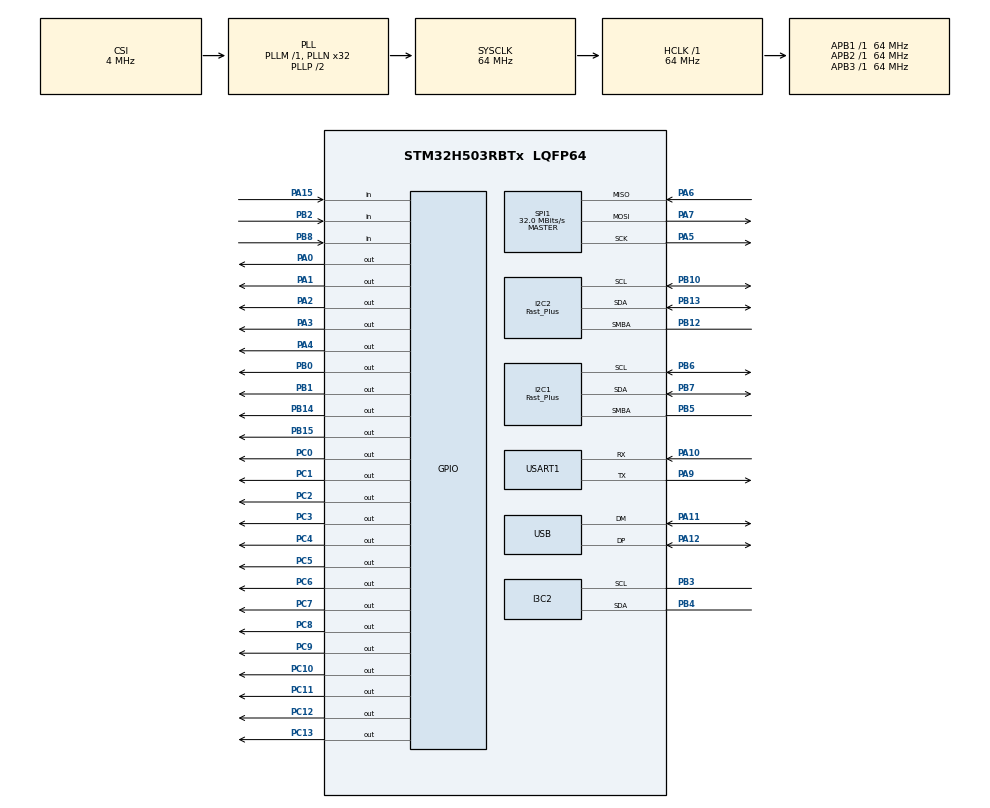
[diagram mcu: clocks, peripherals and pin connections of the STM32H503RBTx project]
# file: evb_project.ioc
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BOOTPATH.BootPathName=LEGACY
BOOTPATH.UserSelectedBootPath=LEGACY
GPDMA1.DIRECTION_GPDMACH0=DMA_MEMORY_TO_PERIPH
GPDMA1.IPHANDLE_GPDMACH0-SIMPLEREQUEST_GPDMACH0=__NULL
GPDMA1.IPHANDLE_GPDMACH1-SIMPLEREQUEST_GPDMACH1=__NULL
GPDMA1.REQUEST_GPDMACH0=GPDMA1_REQUEST_SPI1_TX
GPDMA1.REQUEST_GPDMACH1=GPDMA1_REQUEST_SPI1_RX
I2C1.I2C_Speed_Mode=I2C_Fast_Plus
I2C1.SMBusNoStretchMode=SMBUS_NOSTRETCH_ENABLE
I2C1.Timeout=0x0000830D
I2C1.Timing=0x00300B29
I2C2.I2C_Speed_Mode=I2C_Fast_Plus
I2C2.SMBusNoStretchMode=SMBUS_NOSTRETCH_ENABLE
I2C2.Timeout=0x0000830D
I2C2.Timing=0x00300B29
I3C2.BusFreeDuration=430
I3C2.Register0=0x001e131e
I3C2.Register1=0x000d003e
I3C2.SCLI3CHighDuration=0x13
I3C2.SCLODLowDuration=0x1e
I3C2.SCLPPLowDuration=0x1e
I3C2.SCL_OD_Freq=1255
I3C2.SCL_PP_Freq=1255
I3C2.hexBusFreeDuration=0x0d
I3C2.hexBusIdleDuration=0x3e
Mcu.Family=STM32H5
Mcu.Name=STM32H503RBTx
Mcu.Package=LQFP64
NVIC.GPDMA1_Channel0_IRQn=true\:0\:0\:false\:false\:true\:false\:true\:true
NVIC.GPDMA1_Channel1_IRQn=true\:0\:0\:false\:false\:true\:false\:true\:true
NVIC.I2C1_ER_IRQn=true\:0\:0\:false\:false\:true\:true\:true\:true
NVIC.I2C1_EV_IRQn=true\:0\:0\:false\:false\:true\:true\:true\:true
NVIC.I2C2_ER_IRQn=true\:0\:0\:false\:false\:true\:true\:true\:true
NVIC.I2C2_EV_IRQn=true\:0\:0\:false\:false\:true\:true\:true\:true
NVIC.PriorityGroup=NVIC_PRIORITYGROUP_4
NVIC.SPI1_IRQn=true\:0\:0\:false\:false\:true\:true\:true\:true
NVIC.TIM1_BRK_IRQn=true\:0\:0\:false\:false\:true\:true\:true\:true
NVIC.TIM1_CC_IRQn=true\:0\:0\:false\:false\:true\:true\:true\:true
NVIC.TIM1_TRG_COM_IRQn=true\:0\:0\:false\:false\:true\:true\:true\:true
NVIC.TIM1_UP_IRQn=true\:0\:0\:false\:false\:true\:true\:true\:true
NVIC.USB_DRD_FS_IRQn=true\:0\:0\:false\:false\:true\:true\:true\:true
PA0.Signal=GPIO_Output
PA1.Signal=GPIO_Output
PA10.Mode=Asynchronous
PA10.Signal=USART1_RX
PA11.Mode=Device
PA11.Signal=USB_DM
PA12.Mode=Device
PA12.Signal=USB_DP
PA15(JTDI).Signal=GPIO_Input
PA2.GPIO_PuPd=GPIO_PULLUP
PA2.PinState=GPIO_PIN_SET
PA2.Signal=GPIO_Output
PA3.GPIO_PuPd=GPIO_PULLUP
PA3.PinState=GPIO_PIN_SET
PA3.Signal=GPIO_Output
PA4.GPIO_PuPd=GPIO_PULLUP
PA4.PinState=GPIO_PIN_SET
PA4.Signal=GPIO_Output
PA5.Mode=Full_Duplex_Master
PA5.Signal=SPI1_SCK
PA6.Mode=Full_Duplex_Master
PA6.Signal=SPI1_MISO
PA7.Mode=Full_Duplex_Master
PA7.Signal=SPI1_MOSI
PA9.Mode=Asynchronous
PA9.Signal=USART1_TX
PB0.Signal=GPIO_Output
PB1.Signal=GPIO_Output
PB10.Mode=SMBus-Alert-mode
PB10.Signal=I2C2_SCL
PB12.Mode=SMBus-Alert-mode
PB12.Signal=I2C2_SMBA
PB13.Mode=SMBus-Alert-mode
PB13.Signal=I2C2_SDA
PB14.Signal=GPIO_Output
PB15.Signal=GPIO_Output
PB2.Signal=GPIO_Input
PB3(JTDO/TRACESWO).Mode=Controller
PB3(JTDO/TRACESWO).Signal=I3C2_SCL
PB4(NJTRST).Mode=Controller
PB4(NJTRST).Signal=I3C2_SDA
PB5.Mode=SMBus-Alert-mode
PB5.Signal=I2C1_SMBA
PB6.Mode=SMBus-Alert-mode
PB6.Signal=I2C1_SCL
PB7.Mode=SMBus-Alert-mode
PB7.Signal=I2C1_SDA
PB8.Signal=GPIO_Input
PC0.Signal=GPIO_Output
PC1.Signal=GPIO_Output
PC10.Signal=GPIO_Output
PC11.Signal=GPIO_Output
PC12.Signal=GPIO_Output
PC13.Signal=GPIO_Output
PC14-OSC32_IN(OSC32_IN).Mode=LSE-External-Oscillator
PC14-OSC32_IN(OSC32_IN).Signal=RCC_OSC32_IN
PC15-OSC32_OUT(OSC32_OUT).Mode=LSE-External-Oscillator
PC15-OSC32_OUT(OSC32_OUT).Signal=RCC_OSC32_OUT
PC2.Signal=GPIO_Output
PC3.Signal=GPIO_Output
PC4.Signal=GPIO_Output
PC5.Signal=GPIO_Output
PC6.Signal=GPIO_Output
PC7.Signal=GPIO_Output
PC8.Signal=GPIO_Output
PC9.Signal=GPIO_Output
PH0-OSC_IN(PH0).Mode=HSE-External-Oscillator
PH0-OSC_IN(PH0).Signal=RCC_OSC_IN
PH1-OSC_OUT(PH1).Mode=HSE-External-Oscillator
PH1-OSC_OUT(PH1).Signal=RCC_OSC_OUT
ProjectManager.HeapSize=0x600
ProjectManager.StackSize=0x800
ProjectManager.TargetToolchain=CMake
RCC.ADCFreq_Value=64000000
RCC.AHBFreq_Value=64000000
RCC.APB1Freq_Value=64000000
RCC.APB1TimFreq_Value=64000000
RCC.APB2Freq_Value=64000000
RCC.APB2TimFreq_Value=64000000
RCC.APB3Freq_Value=64000000
RCC.CSI_VALUE=4000000
RCC.CortexFreq_Value=64000000
RCC.EPOD_VALUE=4000000
RCC.HCLKFreq_Value=64000000
RCC.HSE_VALUE=25000000
RCC.HSI48_VALUE=48000000
RCC.HSI_VALUE=64000000
RCC.LSIRC_VALUE=32000
RCC.PLL2FRACN=0
RCC.PLLFRACN=0
RCC.PLLN=32
RCC.SYSCLKFreq_VALUE=64000000
RCC.SYSCLKSource=RCC_SYSCLKSOURCE_PLLCLK
RCC.USBFreq_Value=48000000
RCC.VCOOutputFreq_Value=128000000
SPI1.BaudRatePrescaler=SPI_BAUDRATEPRESCALER_2
SPI1.CLKPhase=SPI_PHASE_2EDGE
SPI1.CalculateBaudRate=32.0 MBits/s
SPI1.DataSize=SPI_DATASIZE_8BIT
SPI1.Direction=SPI_DIRECTION_2LINES
SPI1.Mode=SPI_MODE_MASTER
SPI1.VirtualType=VM_MASTER
TIM1.AutoReloadPreload=TIM_AUTORELOAD_PRELOAD_ENABLE
TIM1.PeriodNoDither=99
TIM1.Prescaler=63999
USART1.VirtualMode-Asynchronous=VM_ASYNC
USB.VirtualMode=Device_Only
VP_BOOTPATH_VS_BOOTPATH.Mode=BP_Activate
VP_CORTEX_M33_NS_VS_Hclk.Mode=Hclk_Mode
VP_GPDMA1_VS_GPDMACH0.Mode=SIMPLEREQUEST_GPDMACH0
VP_GPDMA1_VS_GPDMACH1.Mode=SIMPLEREQUEST_GPDMACH1
VP_MEMORYMAP_VS_MEMORYMAP.Mode=CurAppReg
VP_PWR_VS_LPOM.Mode=PowerOptimisation
VP_PWR_VS_SECSignals.Mode=Security/Privilege
VP_TIM1_VS_ClockSourceINT.Mode=Internal
board=custom

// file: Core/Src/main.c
/* USER CODE BEGIN Header */
/**
  ******************************************************************************
  * @file           : main.c
  * @brief          : Main program body
  ******************************************************************************
  * @attention
  *
  * Copyright (c) 2026 STMicroelectronics.
  * All rights reserved.
  *
  * This software is licensed under terms that can be found in the LICENSE file
  * in the root directory of this software component.
  * If no LICENSE file comes with this software, it is provided AS-IS.
  *
  ******************************************************************************
  */
/* USER CODE END Header */
#include "main.h"

/* USER CODE BEGIN Includes */
#include "stm32h5xx_hal.h"
#include "stm32h5xx_hal_tim.h"
#include "usbd_core.h"
#include "usbd_customhid.h"
#include "usbd_customhid_if.h"
#include "usbd_desc.h"
#include "usbd_composite_builder.h"
#include "stm32h5xx_hal_gpio.h"
#include <stdint.h>
#include <stdio.h>
#include "usb_message_handler.h"
#include "sample_handler.h"

/* USER CODE END Includes */

SMBUS_HandleTypeDef hsmbus1;
SMBUS_HandleTypeDef hsmbus2;

// I3C_HandleTypeDef hi3c2;

SPI_HandleTypeDef hspi1;
DMA_HandleTypeDef handle_GPDMA1_Channel1;
DMA_HandleTypeDef handle_GPDMA1_Channel0;

TIM_HandleTypeDef htim1;

UART_HandleTypeDef huart1;

PCD_HandleTypeDef hpcd_USB_DRD_FS;

void SystemClock_Config(void);
static void MX_GPIO_Init(void);
static void MX_GPDMA1_Init(void);
static void MX_I2C2_SMBUS_Init(void);
static void MX_I2C1_SMBUS_Init(void);
// static void MX_I3C2_Init(void);
static void MX_SPI1_Init(void);
static void MX_TIM1_Init(void);
static void MX_USART1_UART_Init(void);

/* USER CODE BEGIN 0 */

//                   USB
// uint8_t CDC_EpAdd_Inst[3] = {CDC_IN_EP, CDC_OUT_EP, CDC_CMD_EP}; 	/* CDC Endpoint Addresses array */
// uint8_t HID_EpAdd_Inst = HID_EPIN_ADDR;								/* HID Endpoint Address array */
uint8_t CustomHID_EpAdress[2] = {CUSTOM_HID_EPIN_ADDR, CUSTOM_HID_EPOUT_ADDR};								/* HID Endpoint Address array */
USBD_HandleTypeDef hUsbDeviceFS;
// uint8_t hid_report_buffer[SAMPLE_REPORT_SIZE];
uint8_t HID_InstID = 0, CDC_InstID = 0, CUSTOMHID_InstID = 0;
volatile uint8_t current_sampling_enabled = 0;
volatile uint8_t voltage_sampling_enabled = 0;
volatile uint8_t sampling_enabled_once = 0;

/* USER CODE END 0 */

int main(void)
{

  /* MCU Configuration--------------------------------------------------------*/

  /* Reset of all peripherals, Initializes the Flash interface and the Systick. */

  HAL_Init();

  /* Configure the system clock */
  SystemClock_Config();

  /* Initialize all configured peripherals */
  MX_GPIO_Init();
  MX_GPDMA1_Init();
  MX_I2C2_SMBUS_Init();
  MX_I2C1_SMBUS_Init();
  // MX_I3C2_Init();
  MX_SPI1_Init();
  MX_TIM1_Init();
  MX_USART1_UART_Init();
  /* USER CODE BEGIN 2 */

  InitSampleDev();

//                                           USB
  USBD_UsrLog("\r\n=== Welcome to stm32 custom-hid driver! ===");
  /* Initialize the USB Device Library */
  if(USBD_Init(&hUsbDeviceFS, &Class_Desc, 0) != USBD_OK)
    Error_Handler();
  /* Store HID Instance Class ID */
  CUSTOMHID_InstID = hUsbDeviceFS.classId;
  /* Register the HID Class */
#ifdef USE_USBD_COMPOSITE
  if(USBD_RegisterClassComposite(&hUsbDeviceFS, USBD_CUSTOM_HID_CLASS, CLASS_TYPE_CHID, CustomHID_EpAdress) != USBD_OK)
#else
    /* Add Supported Class */
  if(USBD_RegisterClass(&hUsbDeviceFS, &USBD_CUSTOM_HID) != USBD_OK)
#endif /* USE_USBD_COMPOSITE */
    Error_Handler();

#ifdef USE_USBD_COMPOSITE
  /* Add Custom HID Interface Class */
  if (USBD_CMPSIT_SetClassID(&hUsbDeviceFS, CLASS_TYPE_CHID, 0) != 0xFF)
  {
    USBD_CUSTOM_HID_RegisterInterface(&hUsbDeviceFS, &USBD_CustomHID_fops);
  }

  // /* Add CDC Interface Class */
  if (USBD_CMPSIT_SetClassID(&hUsbDeviceFS, CLASS_TYPE_CDC, 0) != 0xFF)
  {
    USBD_CDC_RegisterInterface(&hUsbDeviceFS, &USBD_CDC_Template_fops);
  }
#else
  /* Add Custom HID callbacks */
  USBD_CUSTOM_HID_RegisterInterface(&hUsbDeviceFS, &USBD_CustomHID_fops);

#endif /* USE_USBD_COMPOSITE */

  UsbMsg_Reset();
  USBD_Start(&hUsbDeviceFS);

  /* USER CODE END 2 */

  /* Infinite loop */
  /* USER CODE BEGIN WHILE */
  while (1) {

    while (UsbMsg_ProcessNext()) {
    }

    // if(sampling_enabled_once) {
    //   ClearSampleData();
    //   // SampleCurrentData();
    //   SampleVoltageData();
    //   SendSampleReport();
    //   USBD_ErrLog("Start sampling once ");
    //   sampling_enabled_once = 0;
    // }

    ClearSampleData();

    if (current_sampling_enabled) {
      SampleCurrentData();
    }
    if (voltage_sampling_enabled) {
      SampleVoltageData();
    }

    if(current_sampling_enabled || voltage_sampling_enabled) {
      SendSampleReport();
    }

    /* USER CODE END WHILE */

  }
}

void SystemClock_Config(void)
{
  RCC_OscInitTypeDef RCC_OscInitStruct = {0};
  RCC_ClkInitTypeDef RCC_ClkInitStruct = {0};

  /** Configure the main internal regulator output voltage
  */
  __HAL_PWR_VOLTAGESCALING_CONFIG(PWR_REGULATOR_VOLTAGE_SCALE3);

  while(!__HAL_PWR_GET_FLAG(PWR_FLAG_VOSRDY)) {}

  /** Initializes the RCC Oscillators according to the specified parameters
  * in the RCC_OscInitTypeDef structure.
  */
  RCC_OscInitStruct.OscillatorType = RCC_OSCILLATORTYPE_HSI48|RCC_OSCILLATORTYPE_CSI;
  RCC_OscInitStruct.HSI48State = RCC_HSI48_ON;
  RCC_OscInitStruct.CSIState = RCC_CSI_ON;
  RCC_OscInitStruct.CSICalibrationValue = RCC_CSICALIBRATION_DEFAULT;
  RCC_OscInitStruct.PLL.PLLState = RCC_PLL_ON;
  RCC_OscInitStruct.PLL.PLLSource = RCC_PLL1_SOURCE_CSI;
  RCC_OscInitStruct.PLL.PLLM = 1;
  RCC_OscInitStruct.PLL.PLLN = 32;
  RCC_OscInitStruct.PLL.PLLP = 2;
  RCC_OscInitStruct.PLL.PLLQ = 2;
  RCC_OscInitStruct.PLL.PLLR = 2;
  RCC_OscInitStruct.PLL.PLLRGE = RCC_PLL1_VCIRANGE_2;
  RCC_OscInitStruct.PLL.PLLVCOSEL = RCC_PLL1_VCORANGE_WIDE;
  RCC_OscInitStruct.PLL.PLLFRACN = 0;
  if (HAL_RCC_OscConfig(&RCC_OscInitStruct) != HAL_OK)
  {
    Error_Handler();
  }

  /** Initializes the CPU, AHB and APB buses clocks
  */
  RCC_ClkInitStruct.ClockType = RCC_CLOCKTYPE_HCLK|RCC_CLOCKTYPE_SYSCLK
                              |RCC_CLOCKTYPE_PCLK1|RCC_CLOCKTYPE_PCLK2
                              |RCC_CLOCKTYPE_PCLK3;
  RCC_ClkInitStruct.SYSCLKSource = RCC_SYSCLKSOURCE_PLLCLK;
  RCC_ClkInitStruct.AHBCLKDivider = RCC_SYSCLK_DIV1;
  RCC_ClkInitStruct.APB1CLKDivider = RCC_HCLK_DIV1;
  RCC_ClkInitStruct.APB2CLKDivider = RCC_HCLK_DIV1;
  RCC_ClkInitStruct.APB3CLKDivider = RCC_HCLK_DIV1;

  if (HAL_RCC_ClockConfig(&RCC_ClkInitStruct, FLASH_LATENCY_3) != HAL_OK)
  {
    Error_Handler();
  }

  /** Configure the programming delay
  */
  __HAL_FLASH_SET_PROGRAM_DELAY(FLASH_PROGRAMMING_DELAY_1);
}

static void MX_GPDMA1_Init(void)
{

  /* Peripheral clock enable */
  __HAL_RCC_GPDMA1_CLK_ENABLE();

  /* GPDMA1 interrupt Init */
    HAL_NVIC_SetPriority(GPDMA1_Channel0_IRQn, 0, 0);
    HAL_NVIC_EnableIRQ(GPDMA1_Channel0_IRQn);
    HAL_NVIC_SetPriority(GPDMA1_Channel1_IRQn, 0, 0);
    HAL_NVIC_EnableIRQ(GPDMA1_Channel1_IRQn);

}

static void MX_I2C1_SMBUS_Init(void)
{

  hsmbus1.Instance = I2C1;
  hsmbus1.Init.Timing = 0x00300B29;
  hsmbus1.Init.AnalogFilter = SMBUS_ANALOGFILTER_ENABLE;
  hsmbus1.Init.OwnAddress1 = 2;
  hsmbus1.Init.AddressingMode = SMBUS_ADDRESSINGMODE_7BIT;
  hsmbus1.Init.DualAddressMode = SMBUS_DUALADDRESS_DISABLE;
  hsmbus1.Init.OwnAddress2 = 0;
  hsmbus1.Init.OwnAddress2Masks = SMBUS_OA2_NOMASK;
  hsmbus1.Init.GeneralCallMode = SMBUS_GENERALCALL_DISABLE;
  hsmbus1.Init.NoStretchMode = SMBUS_NOSTRETCH_ENABLE;
  hsmbus1.Init.PacketErrorCheckMode = SMBUS_PEC_DISABLE;
  hsmbus1.Init.PeripheralMode = SMBUS_PERIPHERAL_MODE_SMBUS_SLAVE;
  hsmbus1.Init.SMBusTimeout = 0x0000830D;
  if (HAL_SMBUS_Init(&hsmbus1) != HAL_OK)
  {
    Error_Handler();
  }

  /** configuration Alert Mode
  */
  if (HAL_SMBUS_EnableAlert_IT(&hsmbus1) != HAL_OK)
  {
    Error_Handler();
  }

  /** SMBus Fast mode Plus enable
  */
  if (HAL_SMBUSEx_ConfigFastModePlus(&hsmbus1, SMBUS_FASTMODEPLUS_ENABLE) != HAL_OK)
  {
    Error_Handler();
  }

}

static void MX_I2C2_SMBUS_Init(void)
{

  hsmbus2.Instance = I2C2;
  hsmbus2.Init.Timing = 0x00300B29;
  hsmbus2.Init.AnalogFilter = SMBUS_ANALOGFILTER_ENABLE;
  hsmbus2.Init.OwnAddress1 = 2;
  hsmbus2.Init.AddressingMode = SMBUS_ADDRESSINGMODE_7BIT;
  hsmbus2.Init.DualAddressMode = SMBUS_DUALADDRESS_DISABLE;
  hsmbus2.Init.OwnAddress2 = 0;
  hsmbus2.Init.OwnAddress2Masks = SMBUS_OA2_NOMASK;
  hsmbus2.Init.GeneralCallMode = SMBUS_GENERALCALL_DISABLE;
  hsmbus2.Init.NoStretchMode = SMBUS_NOSTRETCH_ENABLE;
  hsmbus2.Init.PacketErrorCheckMode = SMBUS_PEC_DISABLE;
  hsmbus2.Init.PeripheralMode = SMBUS_PERIPHERAL_MODE_SMBUS_SLAVE;
  hsmbus2.Init.SMBusTimeout = 0x0000830D;
  if (HAL_SMBUS_Init(&hsmbus2) != HAL_OK)
  {
    Error_Handler();
  }

  /** configuration Alert Mode
  */
  if (HAL_SMBUS_EnableAlert_IT(&hsmbus2) != HAL_OK)
  {
    Error_Handler();
  }

  /** SMBus Fast mode Plus enable
  */
  if (HAL_SMBUSEx_ConfigFastModePlus(&hsmbus2, SMBUS_FASTMODEPLUS_ENABLE) != HAL_OK)
  {
    Error_Handler();
  }

}

// /**
//   * @brief I3C2 Initialization Function
//   * @param None
//   * @retval None
//   */
// static void MX_I3C2_Init(void)
// {

//   /* USER CODE BEGIN I3C2_Init 0 */

//   /* USER CODE END I3C2_Init 0 */

//   I3C_FifoConfTypeDef sFifoConfig = {0};
//   I3C_CtrlConfTypeDef sCtrlConfig = {0};

//   /* USER CODE BEGIN I3C2_Init 1 */

//   /* USER CODE END I3C2_Init 1 */
//   hi3c2.Instance = I3C2;
//   hi3c2.Mode = HAL_I3C_MODE_CONTROLLER;
//   hi3c2.Init.CtrlBusCharacteristic.SDAHoldTime = HAL_I3C_SDA_HOLD_TIME_0_5;
//   hi3c2.Init.CtrlBusCharacteristic.WaitTime = HAL_I3C_OWN_ACTIVITY_STATE_0;
//   hi3c2.Init.CtrlBusCharacteristic.SCLPPLowDuration = 0x1e;
//   hi3c2.Init.CtrlBusCharacteristic.SCLI3CHighDuration = 0x13;
//   hi3c2.Init.CtrlBusCharacteristic.SCLODLowDuration = 0x1e;
//   hi3c2.Init.CtrlBusCharacteristic.SCLI2CHighDuration = 0x00;
//   hi3c2.Init.CtrlBusCharacteristic.BusFreeDuration = 0x0d;
//   hi3c2.Init.CtrlBusCharacteristic.BusIdleDuration = 0x3e;
//   if (HAL_I3C_Init(&hi3c2) != HAL_OK)
//   {
//     Error_Handler();
//   }

//   /** Configure FIFO
//   */
//   sFifoConfig.RxFifoThreshold = HAL_I3C_RXFIFO_THRESHOLD_1_4;
//   sFifoConfig.TxFifoThreshold = HAL_I3C_TXFIFO_THRESHOLD_1_4;
//   sFifoConfig.ControlFifo = HAL_I3C_CONTROLFIFO_DISABLE;
//   sFifoConfig.StatusFifo = HAL_I3C_STATUSFIFO_DISABLE;
//   if (HAL_I3C_SetConfigFifo(&hi3c2, &sFifoConfig) != HAL_OK)
//   {
//     Error_Handler();
//   }

//   /** Configure controller
//   */
//   sCtrlConfig.DynamicAddr = 0;
//   sCtrlConfig.StallTime = 0x00;
//   sCtrlConfig.HotJoinAllowed = DISABLE;
//   sCtrlConfig.ACKStallState = DISABLE;
//   sCtrlConfig.CCCStallState = DISABLE;
//   sCtrlConfig.TxStallState = DISABLE;
//   sCtrlConfig.RxStallState = DISABLE;
//   sCtrlConfig.HighKeeperSDA = DISABLE;
//   if (HAL_I3C_Ctrl_Config(&hi3c2, &sCtrlConfig) != HAL_OK)
//   {
//     Error_Handler();
//   }
//   /* USER CODE BEGIN I3C2_Init 2 */

//   /* USER CODE END I3C2_Init 2 */

// }

static void MX_SPI1_Init(void)
{

  /* SPI1 parameter configuration*/
  hspi1.Instance = SPI1;
  hspi1.Init.Mode = SPI_MODE_MASTER;
  hspi1.Init.Direction = SPI_DIRECTION_2LINES;
  hspi1.Init.DataSize = SPI_DATASIZE_8BIT;
  hspi1.Init.CLKPolarity = SPI_POLARITY_LOW;
  hspi1.Init.CLKPhase = SPI_PHASE_2EDGE;
  hspi1.Init.NSS = SPI_NSS_SOFT;
  hspi1.Init.BaudRatePrescaler = SPI_BAUDRATEPRESCALER_8;
  hspi1.Init.FirstBit = SPI_FIRSTBIT_MSB;
  hspi1.Init.TIMode = SPI_TIMODE_DISABLE;
  hspi1.Init.CRCCalculation = SPI_CRCCALCULATION_DISABLE;
  hspi1.Init.CRCPolynomial = 0x7;
  hspi1.Init.NSSPMode = SPI_NSS_PULSE_DISABLE;
  hspi1.Init.NSSPolarity = SPI_NSS_POLARITY_LOW;
  hspi1.Init.FifoThreshold = SPI_FIFO_THRESHOLD_01DATA;
  hspi1.Init.MasterSSIdleness = SPI_MASTER_SS_IDLENESS_00CYCLE;
  hspi1.Init.MasterInterDataIdleness = SPI_MASTER_INTERDATA_IDLENESS_00CYCLE;
  hspi1.Init.MasterReceiverAutoSusp = SPI_MASTER_RX_AUTOSUSP_DISABLE;
  hspi1.Init.MasterKeepIOState = SPI_MASTER_KEEP_IO_STATE_DISABLE;
  hspi1.Init.IOSwap = SPI_IO_SWAP_DISABLE;
  hspi1.Init.ReadyMasterManagement = SPI_RDY_MASTER_MANAGEMENT_INTERNALLY;
  hspi1.Init.ReadyPolarity = SPI_RDY_POLARITY_HIGH;
  if (HAL_SPI_Init(&hspi1) != HAL_OK)
  {
    Error_Handler();
  }

}

static void MX_TIM1_Init(void)
{

  TIM_ClockConfigTypeDef sClockSourceConfig = {0};
  TIM_MasterConfigTypeDef sMasterConfig = {0};

  htim1.Instance = TIM1;
  htim1.Init.Prescaler = 63999;
  htim1.Init.CounterMode = TIM_COUNTERMODE_UP;
  htim1.Init.Period = 99;
  htim1.Init.ClockDivision = TIM_CLOCKDIVISION_DIV1;
  htim1.Init.RepetitionCounter = 0;
  htim1.Init.AutoReloadPreload = TIM_AUTORELOAD_PRELOAD_ENABLE;
  if (HAL_TIM_Base_Init(&htim1) != HAL_OK)
  {
    Error_Handler();
  }
  sClockSourceConfig.ClockSource = TIM_CLOCKSOURCE_INTERNAL;
  if (HAL_TIM_ConfigClockSource(&htim1, &sClockSourceConfig) != HAL_OK)
  {
    Error_Handler();
  }
  sMasterConfig.MasterOutputTrigger = TIM_TRGO_RESET;
  sMasterConfig.MasterOutputTrigger2 = TIM_TRGO2_RESET;
  sMasterConfig.MasterSlaveMode = TIM_MASTERSLAVEMODE_DISABLE;
  if (HAL_TIMEx_MasterConfigSynchronization(&htim1, &sMasterConfig) != HAL_OK)
  {
    Error_Handler();
  }

}

static void MX_USART1_UART_Init(void)
{

  huart1.Instance = USART1;
  huart1.Init.BaudRate = 115200;
  huart1.Init.WordLength = UART_WORDLENGTH_8B;
  huart1.Init.StopBits = UART_STOPBITS_1;
  huart1.Init.Parity = UART_PARITY_NONE;
  huart1.Init.Mode = UART_MODE_TX_RX;
  huart1.Init.HwFlowCtl = UART_HWCONTROL_NONE;
  huart1.Init.OverSampling = UART_OVERSAMPLING_16;
  huart1.Init.OneBitSampling = UART_ONE_BIT_SAMPLE_DISABLE;
  huart1.Init.ClockPrescaler = UART_PRESCALER_DIV1;
  huart1.AdvancedInit.AdvFeatureInit = UART_ADVFEATURE_NO_INIT;
  if (HAL_UART_Init(&huart1) != HAL_OK)
  {
    Error_Handler();
  }
  if (HAL_UARTEx_SetTxFifoThreshold(&huart1, UART_TXFIFO_THRESHOLD_1_8) != HAL_OK)
  {
    Error_Handler();
  }
  if (HAL_UARTEx_SetRxFifoThreshold(&huart1, UART_RXFIFO_THRESHOLD_1_8) != HAL_OK)
  {
    Error_Handler();
  }
  if (HAL_UARTEx_DisableFifoMode(&huart1) != HAL_OK)
  {
    Error_Handler();
  }

}

void MX_USB_PCD_Init(void)
{

  hpcd_USB_DRD_FS.Instance = USB_DRD_FS;
  hpcd_USB_DRD_FS.Init.dev_endpoints = 8;
  hpcd_USB_DRD_FS.Init.speed = USBD_FS_SPEED;
  hpcd_USB_DRD_FS.Init.phy_itface = PCD_PHY_EMBEDDED;
  hpcd_USB_DRD_FS.Init.Sof_enable = DISABLE;
  hpcd_USB_DRD_FS.Init.low_power_enable = DISABLE;
  hpcd_USB_DRD_FS.Init.lpm_enable = DISABLE;
  hpcd_USB_DRD_FS.Init.battery_charging_enable = DISABLE;
  hpcd_USB_DRD_FS.Init.vbus_sensing_enable = DISABLE;
  hpcd_USB_DRD_FS.Init.bulk_doublebuffer_enable = DISABLE;
  hpcd_USB_DRD_FS.Init.iso_singlebuffer_enable = DISABLE;
  if (HAL_PCD_Init(&hpcd_USB_DRD_FS) != HAL_OK)
  {
    Error_Handler();
  }

}

static void MX_GPIO_Init(void)
{
  GPIO_InitTypeDef GPIO_InitStruct = {0};

  /* GPIO Ports Clock Enable */
  __HAL_RCC_GPIOC_CLK_ENABLE();
  __HAL_RCC_GPIOA_CLK_ENABLE();
  __HAL_RCC_GPIOB_CLK_ENABLE();
  __HAL_RCC_GPIOD_CLK_ENABLE();

  /*Configure GPIO pin Output Level */
  HAL_GPIO_WritePin(GPIOC, GPIO_PIN_13|GPIO_PIN_0|GPIO_PIN_1|GPIO_PIN_2
                          |GPIO_PIN_3|GPIO_PIN_4|GPIO_PIN_5|GPIO_PIN_6
                          |GPIO_PIN_7|GPIO_PIN_8|GPIO_PIN_9|GPIO_PIN_10
                          |GPIO_PIN_11|GPIO_PIN_12, GPIO_PIN_RESET);

  /*Configure GPIO pin Output Level */
  HAL_GPIO_WritePin(GPIOA, GPIO_PIN_0|GPIO_PIN_1, GPIO_PIN_RESET);

  /*Configure GPIO pin Output Level */
  HAL_GPIO_WritePin(GPIOA, GPIO_PIN_2|GPIO_PIN_3|GPIO_PIN_4, GPIO_PIN_SET);

  /*Configure GPIO pin Output Level */
  HAL_GPIO_WritePin(GPIOB, GPIO_PIN_0|GPIO_PIN_1|GPIO_PIN_8|GPIO_PIN_14|GPIO_PIN_15, GPIO_PIN_RESET);

  /*Configure GPIO pin Output Level */
  HAL_GPIO_WritePin(GPIOD, GPIO_PIN_2, GPIO_PIN_RESET);

  /*Configure GPIO pins : PC13 PC0 PC1 PC2
                           PC3 PC4 PC5 PC6
                           PC7 PC8 PC9 PC10
                           PC11 PC12 */
  GPIO_InitStruct.Pin = GPIO_PIN_13|GPIO_PIN_0|GPIO_PIN_1|GPIO_PIN_2
                          |GPIO_PIN_3|GPIO_PIN_4|GPIO_PIN_5|GPIO_PIN_6
                          |GPIO_PIN_7|GPIO_PIN_8|GPIO_PIN_9|GPIO_PIN_10
                          |GPIO_PIN_11|GPIO_PIN_12;
  GPIO_InitStruct.Mode = GPIO_MODE_OUTPUT_PP;
  GPIO_InitStruct.Pull = GPIO_NOPULL;
  GPIO_InitStruct.Speed = GPIO_SPEED_FREQ_LOW;
  HAL_GPIO_Init(GPIOC, &GPIO_InitStruct);

  /*Configure GPIO pins : PA0 PA1 */
  GPIO_InitStruct.Pin = GPIO_PIN_0|GPIO_PIN_1;
  GPIO_InitStruct.Mode = GPIO_MODE_OUTPUT_PP;
  GPIO_InitStruct.Pull = GPIO_NOPULL;
  GPIO_InitStruct.Speed = GPIO_SPEED_FREQ_LOW;
  HAL_GPIO_Init(GPIOA, &GPIO_InitStruct);

  /*Configure GPIO pins : PA2 PA3 PA4 */
  GPIO_InitStruct.Pin = GPIO_PIN_2|GPIO_PIN_3|GPIO_PIN_4;
  GPIO_InitStruct.Mode = GPIO_MODE_OUTPUT_PP;
  GPIO_InitStruct.Pull = GPIO_PULLUP;
  GPIO_InitStruct.Speed = GPIO_SPEED_FREQ_LOW;
  HAL_GPIO_Init(GPIOA, &GPIO_InitStruct);

  /*Configure GPIO pins : PB0 PB1 PB14 PB15 */
  GPIO_InitStruct.Pin = GPIO_PIN_0|GPIO_PIN_1|GPIO_PIN_14|GPIO_PIN_15;
  GPIO_InitStruct.Mode = GPIO_MODE_OUTPUT_PP;
  GPIO_InitStruct.Pull = GPIO_NOPULL;
  GPIO_InitStruct.Speed = GPIO_SPEED_FREQ_LOW;
  HAL_GPIO_Init(GPIOB, &GPIO_InitStruct);

  /*Configure GPIO pin : PB2 */
  GPIO_InitStruct.Pin = GPIO_PIN_2;
  GPIO_InitStruct.Mode = GPIO_MODE_INPUT;
  GPIO_InitStruct.Pull = GPIO_NOPULL;
  HAL_GPIO_Init(GPIOB, &GPIO_InitStruct);

  /*Configure GPIO pin : PB8 */
  GPIO_InitStruct.Pin = GPIO_PIN_8;
  GPIO_InitStruct.Mode = GPIO_MODE_OUTPUT_PP;
  GPIO_InitStruct.Pull = GPIO_NOPULL;
  GPIO_InitStruct.Speed = GPIO_SPEED_FREQ_LOW;
  HAL_GPIO_Init(GPIOB, &GPIO_InitStruct);

  /*Configure GPIO pin : PD2 */
  GPIO_InitStruct.Pin = GPIO_PIN_2;
  GPIO_InitStruct.Mode = GPIO_MODE_OUTPUT_PP;
  GPIO_InitStruct.Pull = GPIO_NOPULL;
  GPIO_InitStruct.Speed = GPIO_SPEED_FREQ_LOW;
  HAL_GPIO_Init(GPIOD, &GPIO_InitStruct);

  /*Configure GPIO pin : PA15 */
  GPIO_InitStruct.Pin = GPIO_PIN_15;
  GPIO_InitStruct.Mode = GPIO_MODE_INPUT;
  GPIO_InitStruct.Pull = GPIO_NOPULL;
  HAL_GPIO_Init(GPIOA, &GPIO_InitStruct);

}

/* USER CODE BEGIN 4 */
 void HAL_TIM_PeriodElapsedCallback(TIM_HandleTypeDef *htim){

 }
/* USER CODE END 4 */

void Error_Handler(void)
{
  __disable_irq();
  while (1)
  {
  }
}
